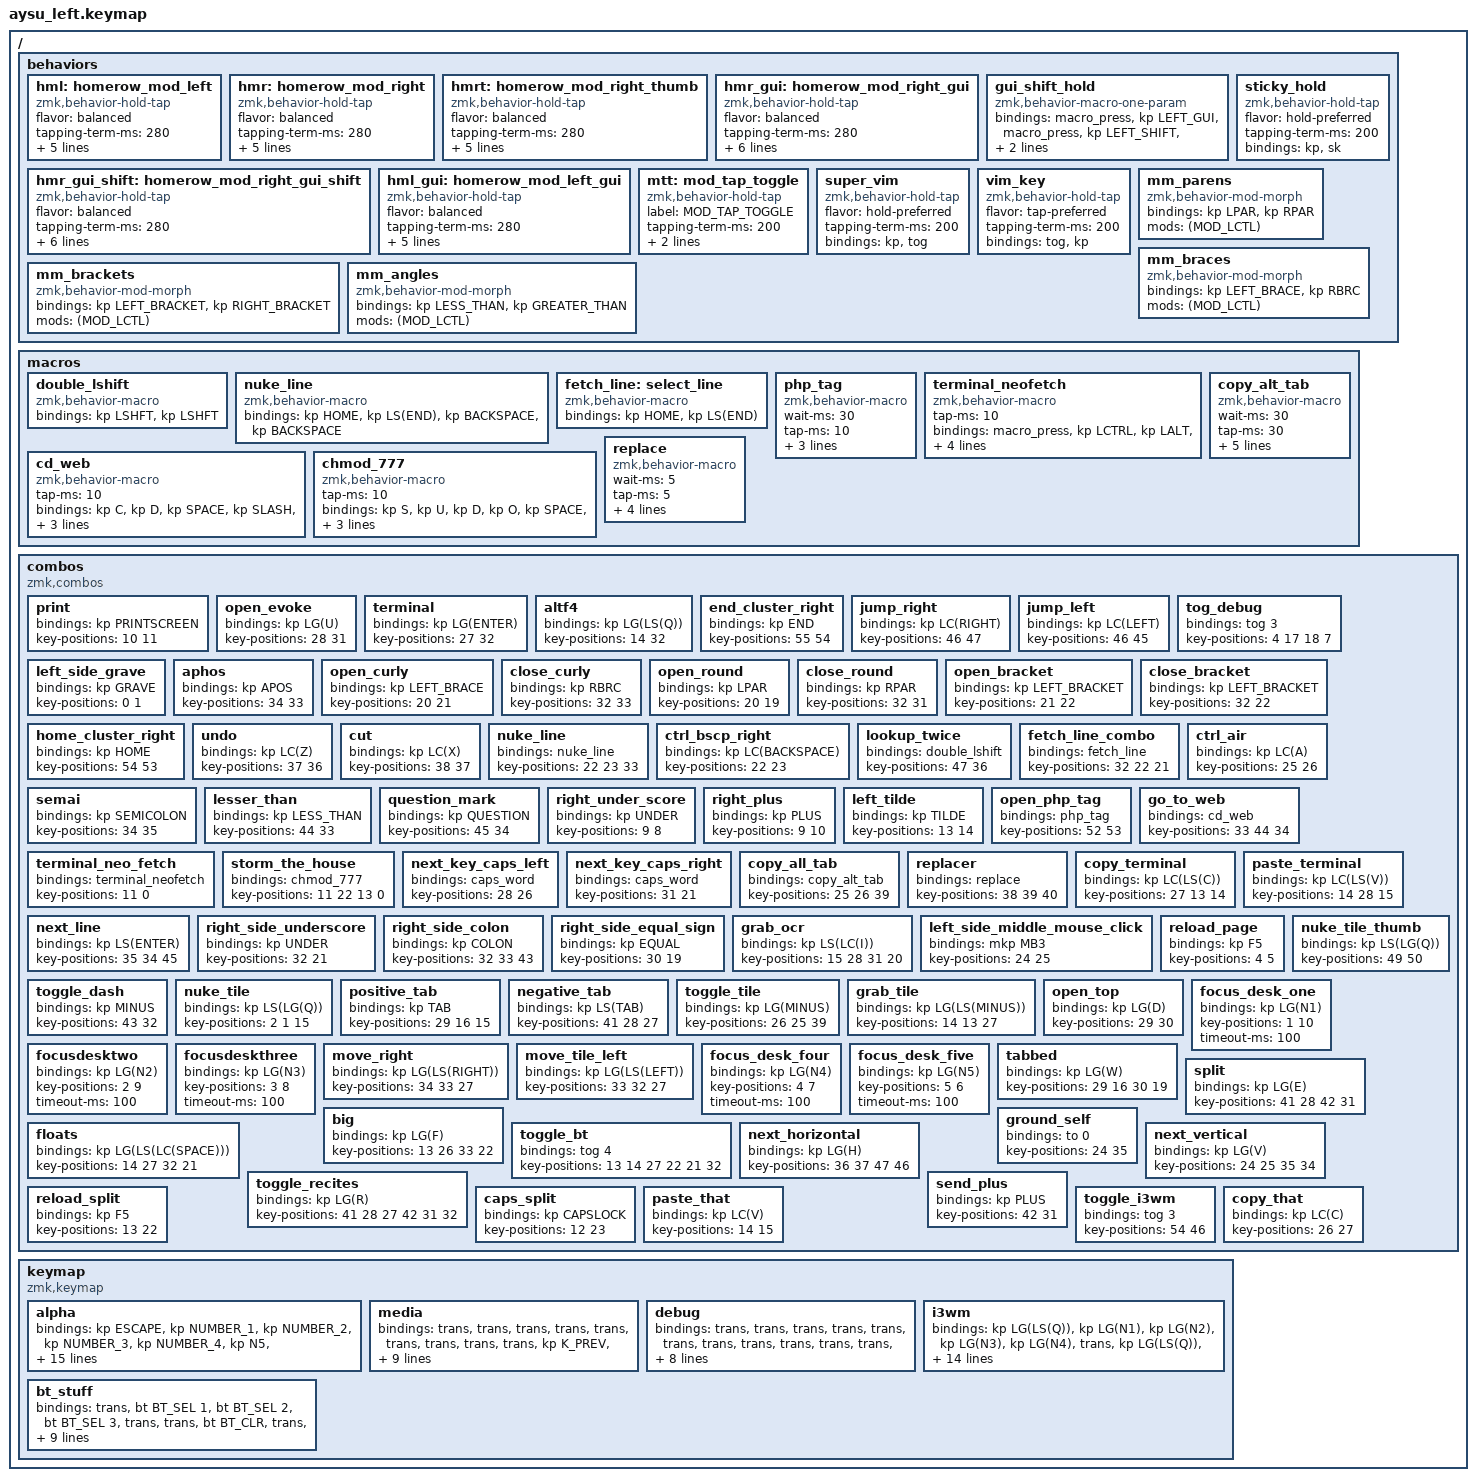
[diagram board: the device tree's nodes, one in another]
#include <dt-bindings/zmk/modifiers.h>
#include <behaviors.dtsi>
#include <dt-bindings/zmk/bt.h>
#include <dt-bindings/zmk/keys.h>
#include <dt-bindings/zmk/pointing.h>

#define ALPHA 0
#define SYM 1
#define NAV 2

// Position lists for positional hold-tap
// Left-hand keys

#define KEYS_L  0  1  2  3  4  5  \
               12 13 14 15 16 17   \
               24 25 26 27 28 29   \
               36 37 38 39 40 41

// Right-hand keys

#define KEYS_R  6  7  8  9  10 11  \
               18 19 20 21 22 23   \
               30 31 32 33 34 35   \
               42 43 44 45 46 47

// Thumb keys

#define THUMBS 48 49 50 51 52 53 54 55

/ {
    behaviors {
        // Left-hand Homerow Mods (u/urob timeless HRM)

        hml: homerow_mod_left {
            compatible = "zmk,behavior-hold-tap";
            #binding-cells = <2>;
            flavor = "balanced";
            tapping-term-ms = <280>;
            quick-tap-ms = <175>;
            require-prior-idle-ms = <150>;
            bindings = <&kp>, <&kp>;

            hold-trigger-key-positions = <KEYS_R THUMBS>;
            hold-trigger-on-release;
        };

        // Right-hand Homerow Mods

        hmr: homerow_mod_right {
            compatible = "zmk,behavior-hold-tap";
            #binding-cells = <2>;
            flavor = "balanced";
            tapping-term-ms = <280>;
            quick-tap-ms = <175>;
            require-prior-idle-ms = <150>;
            bindings = <&kp>, <&kp>;

            hold-trigger-key-positions = <KEYS_L THUMBS>;
            hold-trigger-on-release;
        };

        // Right-hand Homerow Mods for thumb keys (no THUMBS in positions)

        hmrt: homerow_mod_right_thumb {
            compatible = "zmk,behavior-hold-tap";
            #binding-cells = <2>;
            flavor = "balanced";
            tapping-term-ms = <280>;
            quick-tap-ms = <175>;
            require-prior-idle-ms = <150>;
            bindings = <&kp>, <&kp>;

            hold-trigger-key-positions = <KEYS_L>;
            hold-trigger-on-release;
        };

        // Right-hand GUI mod (number keys only)

        hmr_gui: homerow_mod_right_gui {
            compatible = "zmk,behavior-hold-tap";
            #binding-cells = <2>;
            flavor = "balanced";
            tapping-term-ms = <280>;
            quick-tap-ms = <175>;
            require-prior-idle-ms = <150>;
            bindings = <&kp>, <&kp>;

            hold-trigger-key-positions = <1 2 3 4 5 6 7 8 9 10>;
            hold-trigger-on-release;
        };

        // Hold: GUI+Shift pressed together, released on key up

        gui_shift_hold: gui_shift_hold {
            compatible = "zmk,behavior-macro-one-param";
            #binding-cells = <1>;
            bindings =
                <&macro_press>,
                <&kp LEFT_GUI>,
                <&macro_press>,
                <&kp LEFT_SHIFT>,
                <&macro_pause_for_release>,
                <&macro_release>,
                <&kp LEFT_SHIFT>,
                <&macro_release>,
                <&kp LEFT_GUI>;
        };

        // Right-hand GUI+Shift mod (number keys only)

        hmr_gui_shift: homerow_mod_right_gui_shift {
            compatible = "zmk,behavior-hold-tap";
            #binding-cells = <2>;
            flavor = "balanced";
            tapping-term-ms = <280>;
            quick-tap-ms = <175>;
            require-prior-idle-ms = <150>;
            bindings = <&gui_shift_hold>, <&kp>;

            hold-trigger-key-positions = <1 2 3 4 5 6 7 8 9 10>;
            hold-trigger-on-release;
        };

        // Left-hand GUI mod (arrow keys only)

        hml_gui: homerow_mod_left_gui {
            compatible = "zmk,behavior-hold-tap";
            #binding-cells = <2>;
            flavor = "balanced";
            tapping-term-ms = <280>;
            quick-tap-ms = <175>;
            require-prior-idle-ms = <150>;
            bindings = <&kp>, <&kp>;

            hold-trigger-key-positions = <52 53 54 55>;
            hold-trigger-on-release;
        };

        // Tap = sticky-shift, Hold = regular shift
        // Usage: &sticky_hold LSHIFT

        sticky_hold: sticky_hold {
            compatible = "zmk,behavior-hold-tap";
            #binding-cells = <2>;
            flavor = "hold-preferred";
            tapping-term-ms = <200>;
            bindings = <&kp>, <&sk>;
        };

        // Hold -> Key Press (Modifier), Tap -> Toggle Layer
        // Usage: &mtt LSHIFT 1 (Hold Shift, Tap Toggle Layer 1)

        mtt: mod_tap_toggle {
            compatible = "zmk,behavior-hold-tap";
            label = "MOD_TAP_TOGGLE";
            #binding-cells = <2>;
            tapping-term-ms = <200>;
            flavor = "hold-preferred";
            bindings = <&kp>, <&tog>;
        };

        super_vim: super_vim {
            compatible = "zmk,behavior-hold-tap";
            #binding-cells = <2>;
            flavor = "hold-preferred";
            tapping-term-ms = <200>;
            bindings = <&kp>, <&tog>;
        };

        vim_key: vim_key {
            compatible = "zmk,behavior-hold-tap";
            #binding-cells = <2>;
            flavor = "tap-preferred";
            tapping-term-ms = <200>;
            bindings = <&tog>, <&kp>;
        };

        // Usage: &super_vim LGUI VIM_LAYER

        mm_parens: mm_parens {
            compatible = "zmk,behavior-mod-morph";
            #binding-cells = <0>;
            bindings = <&kp LPAR>, <&kp RPAR>;

            mods = <(MOD_LCTL)>;
        };

        mm_braces: mm_braces {
            compatible = "zmk,behavior-mod-morph";
            #binding-cells = <0>;
            bindings = <&kp LEFT_BRACE>, <&kp RBRC>;

            mods = <(MOD_LCTL)>;
        };

        mm_brackets: mm_brackets {
            compatible = "zmk,behavior-mod-morph";
            #binding-cells = <0>;
            bindings = <&kp LEFT_BRACKET>, <&kp RIGHT_BRACKET>;

            mods = <(MOD_LCTL)>;
        };

        mm_angles: mm_angles {
            compatible = "zmk,behavior-mod-morph";
            #binding-cells = <0>;
            bindings = <&kp LESS_THAN>, <&kp GREATER_THAN>;

            mods = <(MOD_LCTL)>;
        };
    };

    macros {
        double_lshift: double_lshift {
            compatible = "zmk,behavior-macro";
            #binding-cells = <0>;
            bindings = <&kp LSHFT &kp LSHFT>;
        };

        nuke_line: nuke_line {
            compatible = "zmk,behavior-macro";
            #binding-cells = <0>;
            bindings = <&kp HOME &kp LS(END) &kp BACKSPACE &kp BACKSPACE>;
        };

        fetch_line: select_line {
            compatible = "zmk,behavior-macro";
            #binding-cells = <0>;
            bindings = <&kp HOME &kp LS(END)>;
        };

        php_tag: php_tag {
            compatible = "zmk,behavior-macro";
            #binding-cells = <0>;
            wait-ms = <30>;
            tap-ms = <10>;
            bindings = <&kp LT &kp QMARK &kp P &kp H &kp P &kp SPACE &kp SPACE &kp QMARK &kp GT &kp LEFT &kp LEFT &kp LEFT>;
        };

        terminal_neofetch: terminal_neofetch {
            compatible = "zmk,behavior-macro";
            #binding-cells = <0>;
            tap-ms = <10>;  // Duration of each press
            bindings =
                <&macro_press>,
                <&kp LCTRL &kp LALT>,
                <&macro_tap>,
                <&kp T>,
                <&macro_release>,
                <&kp LCTRL &kp LALT>,
                <&macro_wait_time 1000>,
                <&macro_tap>,
                <&kp N &kp E &kp O &kp F &kp E &kp T &kp C &kp H &kp RET>;
        };

        cd_web: cd_web {
            compatible = "zmk,behavior-macro";
            #binding-cells = <0>;
            tap-ms = <10>;
            bindings = <&kp C &kp D &kp SPACE &kp SLASH &kp V &kp A &kp R &kp SLASH &kp W &kp W &kp W &kp SLASH &kp H &kp T &kp M &kp L &kp RET>;
        };

        chmod_777: chmod_777 {
            compatible = "zmk,behavior-macro";
            #binding-cells = <0>;
            tap-ms = <10>;
            bindings = <&kp S &kp U &kp D &kp O &kp SPACE &kp C &kp H &kp M &kp O &kp D &kp SPACE &kp N7 &kp N7 &kp N7 &kp SPACE &kp MINUS &kp LS(R) &kp SPACE &kp DOT &kp SLASH &kp RET>;
        };

        copy_alt_tab: copy_alt_tab {
            compatible = "zmk,behavior-macro";
            #binding-cells = <0>;
            wait-ms = <30>;
            tap-ms = <30>;
            bindings =
                <&macro_press>,
                <&kp LCTRL>,
                <&macro_tap>,
                <&kp A>,
                <&macro_release>,
                <&kp LCTRL>,
                <&macro_press>,
                <&kp LCTRL>,
                <&macro_tap>,
                <&kp C>,
                <&macro_release>,
                <&kp LCTRL>,
                <&macro_press>,
                <&kp LALT>,
                <&macro_tap>,
                <&kp TAB>,
                <&macro_release>,
                <&kp LALT>;
        };

        replace: replace {
            compatible = "zmk,behavior-macro";
            #binding-cells = <0>;
            wait-ms = <5>;
            tap-ms = <5>;
            bindings =
                <&macro_press>,
                <&kp LCTRL>,
                <&macro_tap>,
                <&kp A>,
                <&macro_release>,
                <&kp LCTRL>,
                <&macro_wait_time 20>,
                <&macro_press>,
                <&kp LCTRL>,
                <&macro_tap>,
                <&kp V>,
                <&macro_release>,
                <&kp LCTRL>;
        };
    };

    combos {
        compatible = "zmk,combos";

        print {
            bindings = <&kp PRINTSCREEN>;
            key-positions = <10 11>;
        };

        open_evoke {
            bindings = <&kp LG(U)>;
            key-positions = <28 31>;
        };

        terminal {
            bindings = <&kp LG(ENTER)>;
            key-positions = <27 32>;
        };

        altf4 {
            bindings = <&kp LG(LS(Q))>;
            key-positions = <14 32>;
        };

        end_cluster_right {
            bindings = <&kp END>;
            key-positions = <55 54>;
        };

        jump_right {
            bindings = <&kp LC(RIGHT)>;
            key-positions = <46 47>;
        };

        jump_left {
            bindings = <&kp LC(LEFT)>;
            key-positions = <46 45>;
        };

        tog_debug {
            bindings = <&tog 3>;
            key-positions = <4 17 18 7>;
        };

        left_side_grave {
            bindings = <&kp GRAVE>;
            key-positions = <0 1>;
        };

        aphos {
            bindings = <&kp APOS>;
            key-positions = <34 33>;
        };

        open_curly {
            bindings = <&kp LEFT_BRACE>;
            key-positions = <20 21>;
        };

        close_curly {
            bindings = <&kp RBRC>;
            key-positions = <32 33>;
        };

        open_round {
            bindings = <&kp LPAR>;
            key-positions = <20 19>;
        };

        close_round {
            bindings = <&kp RPAR>;
            key-positions = <32 31>;
        };

        open_bracket {
            bindings = <&kp LEFT_BRACKET>;
            key-positions = <21 22>;
        };

        close_bracket {
            bindings = <&kp LEFT_BRACKET>;
            key-positions = <32 22>;
        };

        home_cluster_right {
            bindings = <&kp HOME>;
            key-positions = <54 53>;
        };

        undo {
            bindings = <&kp LC(Z)>;
            key-positions = <37 36>;
        };

        cut {
            bindings = <&kp LC(X)>;
            key-positions = <38 37>;
        };

        nuke_line {
            bindings = <&nuke_line>;
            key-positions = <22 23 33>;
        };

        ctrl_bscp_right {
            bindings = <&kp LC(BACKSPACE)>;
            key-positions = <22 23>;
        };

        lookup_twice {
            bindings = <&double_lshift>;
            key-positions = <47 36>;
        };

        fetch_line_combo {
            bindings = <&fetch_line>;
            key-positions = <32 22 21>;
        };

        ctrl_air {
            bindings = <&kp LC(A)>;
            key-positions = <25 26>;
        };

        semai {
            bindings = <&kp SEMICOLON>;
            key-positions = <34 35>;
        };

        lesser_than {
            bindings = <&kp LESS_THAN>;
            key-positions = <44 33>;
        };

        question_mark {
            bindings = <&kp QUESTION>;
            key-positions = <45 34>;
        };

        right_under_score {
            bindings = <&kp UNDER>;
            key-positions = <9 8>;
        };

        right_plus {
            bindings = <&kp PLUS>;
            key-positions = <9 10>;
        };

        left_tilde {
            bindings = <&kp TILDE>;
            key-positions = <13 14>;
        };

        open_php_tag {
            bindings = <&php_tag>;
            key-positions = <52 53>;
        };

        go_to_web {
            bindings = <&cd_web>;
            key-positions = <33 44 34>;
        };

        terminal_neo_fetch {
            bindings = <&terminal_neofetch>;
            key-positions = <11 0>;
        };

        storm_the_house {
            bindings = <&chmod_777>;
            key-positions = <11 22 13 0>;
        };

        next_key_caps_left {
            bindings = <&caps_word>;
            key-positions = <28 26>;
        };

        next_key_caps_right {
            bindings = <&caps_word>;
            key-positions = <31 21>;
        };

        copy_all_tab {
            bindings = <&copy_alt_tab>;
            key-positions = <25 26 39>;
        };

        replacer {
            bindings = <&replace>;
            key-positions = <38 39 40>;
        };

        copy_terminal {
            bindings = <&kp LC(LS(C))>;
            key-positions = <27 13 14>;
        };

        paste_terminal {
            bindings = <&kp LC(LS(V))>;
            key-positions = <14 28 15>;
        };

        next_line {
            bindings = <&kp LS(ENTER)>;
            key-positions = <35 34 45>;
        };

        right_side_underscore {
            bindings = <&kp UNDER>;
            key-positions = <32 21>;
        };

        right_side_colon {
            bindings = <&kp COLON>;
            key-positions = <32 33 43>;
        };

        right_side_equal_sign {
            bindings = <&kp EQUAL>;
            key-positions = <30 19>;
        };

        grab_ocr {
            bindings = <&kp LS(LC(I))>;
            key-positions = <15 28 31 20>;
        };

        left_side_middle_mouse_click {
            bindings = <&mkp MB3>;
            key-positions = <24 25>;
        };

        reload_page {
            bindings = <&kp F5>;
            key-positions = <4 5>;
        };

        nuke_tile_thumb {
            bindings = <&kp LS(LG(Q))>;
            key-positions = <49 50>;
        };

        toggle_dash {
            bindings = <&kp MINUS>;
            key-positions = <43 32>;
        };

        nuke_tile {
            bindings = <&kp LS(LG(Q))>;
            key-positions = <2 1 15>;
        };

        positive_tab {
            bindings = <&kp TAB>;
            key-positions = <29 16 15>;
        };

        negative_tab {
            bindings = <&kp LS(TAB)>;
            key-positions = <41 28 27>;
        };

        toggle_tile {
            bindings = <&kp LG(MINUS)>;
            key-positions = <26 25 39>;
        };

        grab_tile {
            bindings = <&kp LG(LS(MINUS))>;
            key-positions = <14 13 27>;
        };

        open_top {
            bindings = <&kp LG(D)>;
            key-positions = <29 30>;
        };

        focus_desk_one {
            bindings = <&kp LG(N1)>;
            key-positions = <1 10>;
            timeout-ms = <100>;
        };

        focusdesktwo {
            bindings = <&kp LG(N2)>;
            key-positions = <2 9>;
            timeout-ms = <100>;
        };

        focusdeskthree {
            bindings = <&kp LG(N3)>;
            key-positions = <3 8>;
            timeout-ms = <100>;
        };

        move_right {
            bindings = <&kp LG(LS(RIGHT))>;
            key-positions = <34 33 27>;
        };

        move_tile_left {
            bindings = <&kp LG(LS(LEFT))>;
            key-positions = <33 32 27>;
        };

        focus_desk_four {
            bindings = <&kp LG(N4)>;
            key-positions = <4 7>;
            timeout-ms = <100>;
        };

        focus_desk_five {
            bindings = <&kp LG(N5)>;
            key-positions = <5 6>;
            timeout-ms = <100>;
        };

        tabbed {
            bindings = <&kp LG(W)>;
            key-positions = <29 16 30 19>;
        };

        split {
            bindings = <&kp LG(E)>;
            key-positions = <41 28 42 31>;
        };

        big {
            bindings = <&kp LG(F)>;
            key-positions = <13 26 33 22>;
        };

        floats {
            bindings = <&kp LG(LS(LC(SPACE)))>;
            key-positions = <14 27 32 21>;
        };

        toggle_bt {
            bindings = <&tog 4>;
            key-positions = <13 14 27 22 21 32>;
        };

        ground_self {
            bindings = <&to 0>;
            key-positions = <24 35>;
        };

        next_horizontal {
            bindings = <&kp LG(H)>;
            key-positions = <36 37 47 46>;
        };

        next_vertical {
            bindings = <&kp LG(V)>;
            key-positions = <24 25 35 34>;
        };

        toggle_recites {
            bindings = <&kp LG(R)>;
            key-positions = <41 28 27 42 31 32>;
        };

        send_plus {
            bindings = <&kp PLUS>;
            key-positions = <42 31>;
        };

        reload_split {
            bindings = <&kp F5>;
            key-positions = <13 22>;
        };

        caps_split {
            bindings = <&kp CAPSLOCK>;
            key-positions = <12 23>;
        };

        paste_that {
            bindings = <&kp LC(V)>;
            key-positions = <14 15>;
        };

        toggle_i3wm {
            bindings = <&tog 3>;
            key-positions = <54 46>;
        };

        copy_that {
            bindings = <&kp LC(C)>;
            key-positions = <26 27>;
        };
    };

    keymap {
        compatible = "zmk,keymap";

        alpha {
            bindings = <
&kp ESCAPE  &kp NUMBER_1  &kp NUMBER_2  &kp NUMBER_3  &kp NUMBER_4  &kp N5  &kp NUMBER_6  &kp N7  &kp N8  &kp N9  &kp N0  &kp LC(LS(O))  &mt LEFT_GUI BACKSLASH  &kp Q  &hml LCTRL W  &hml_gui LEFT_GUI E  &kp R  &kp T  &kp Y  &kp U  &kp I  &kp O  &kp P  &kp BSPC  &mkp MB1  &kp A  &kp S  &kp D  &kp F  &kp G  &kp H  &kp N  &kp M  &kp L  &kp SPACE  &kp RET  &sticky_hold LSHFT LEFT_SHIFT  &mt LEFT_ALT Z  &kp X  &kp C  &kp V  &kp B  &kp LC(LS(O))  &kp J  &kp K  &kp COMMA  &mt RIGHT_ALT DOT  &mt RIGHT_SHIFT SLASH  &kp LCTRL  &mt (LALT) LC(LS(O))  &mt (LEFT_SHIFT) LC(C)  &mt (TAB) LC(V)  &kp DOWN  &hmrt LEFT_ALT UP_ARROW  &hmrt LEFT_SHIFT LEFT_ARROW  &hmr_gui LEFT_GUI RIGHT_ARROW
            >;
        };

        media {
            bindings = <
&trans  &trans  &trans  &trans  &trans  &trans  &trans  &trans  &trans  &kp K_PREV  &kp C_NEXT  &kp C_FF  &trans  &trans  &trans  &trans  &trans  &trans  &trans  &trans  &trans  &trans  &tog 1  &kp K_VOLUME_UP  &trans  &trans  &trans  &trans  &trans  &trans  &trans  &trans  &trans  &trans  &trans  &kp C_PLAY_PAUSE  &trans  &trans  &trans  &trans  &trans  &trans  &trans  &trans  &trans  &trans  &trans  &kp K_VOLUME_DOWN  &trans  &trans  &trans  &trans  &trans  &trans  &trans  &trans
            >;
        };

        debug {
            bindings = <
&trans  &trans  &trans  &trans  &trans  &trans  &trans  &trans  &trans  &trans  &trans  &trans  &trans  &trans  &trans  &trans  &trans  &trans  &trans  &trans  &trans  &trans  &trans  &trans  &trans  &trans  &trans  &trans  &trans  &trans  &kp LC(O)  &trans  &trans  &trans  &trans  &trans  &trans  &trans  &trans  &trans  &trans  &trans  &kp LC(F2)  &trans  &kp LA(TAB)  &kp F5  &trans  &trans  &trans  &trans  &trans  &trans  &kp F9  &kp F8  &kp F7  &kp LS(F8)
            >;
        };

        i3wm {
            bindings = <
&kp LG(LS(Q))  &kp LG(N1)  &kp LG(N2)  &kp LG(N3)  &kp LG(N4)  &trans  &kp LG(LS(Q))  &trans  &trans  &trans  &trans  &kp LS(LG(R))  &trans  &kp LG(LS(N1))  &kp LG(LS(N2))  &kp LG(LS(N3))  &kp LG(LS(N4))  &kp LG(R)  &trans  &kp LG(LS(UP_ARROW))  &kp LG(LS(RIGHT))  &kp LG(UP_ARROW)  &kp LG(RIGHT)  &trans  &kp LEFT_SHIFT  &kp LG(F)  &kp LG(LS(SPACE))  &kp LG(E)  &kp LG(D)  &kp LG(W)  &kp LG(LS(LEFT))  &kp LG(LS(DOWN))  &kp LG(LEFT)  &kp LG(DOWN)  &kp LG(ENTER)  &trans  &trans  &kp LG(ENTER)  &kp LG(LS(MINUS))  &kp LG(H)  &kp LG(V)  &to 0  &to 0  &trans  &trans  &kp LG(ENTER)  &kp LG(U)  &trans  &trans  &to 0  &trans  &kp LG(MINUS)  &kp DOWN  &kp UP_ARROW  &kp LEFT  &kp RIGHT
            >;
        };

        bt_stuff {
            bindings = <
&trans  &bt BT_SEL 1  &bt BT_SEL 2  &bt BT_SEL 3  &trans  &trans  &bt BT_CLR  &trans  &trans  &trans  &trans  &bt BT_CLR_ALL  &trans  &trans  &trans  &trans  &trans  &trans  &trans  &trans  &trans  &trans  &trans  &trans  &trans  &trans  &trans  &trans  &trans  &trans  &trans  &trans  &trans  &trans  &trans  &trans  &trans  &trans  &trans  &trans  &trans  &trans  &trans  &trans  &trans  &trans  &trans  &trans  &trans  &trans  &trans  &trans  &trans  &trans  &trans  &kp LG(U)
            >;
        };
    };
};
